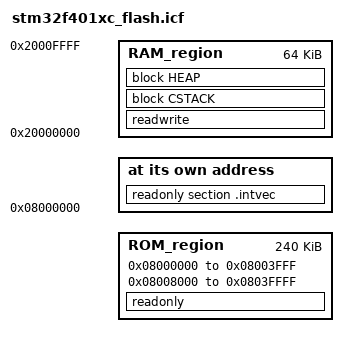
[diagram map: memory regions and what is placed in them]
/*###ICF### Section handled by ICF editor, don't touch! ****/
/*-Editor annotation file-*/
/* IcfEditorFile="$TOOLKIT_DIR$\config\ide\IcfEditor\cortex_v1_0.xml" */
/*-Specials-*/
define symbol __ICFEDIT_intvec_start__ = 0x08000000;
/*-Memory Regions-*/
define symbol __ICFEDIT_region_ROM_start__    = 0x08000000;
define symbol __ICFEDIT_region_ROM_end__      = 0x0803FFFF;
define symbol __ICFEDIT_region_RAM_start__    = 0x20000000;
define symbol __ICFEDIT_region_RAM_end__      = 0x2000FFFF;
/*-Sizes-*/
define symbol __ICFEDIT_size_cstack__ = 0x1000;
define symbol __ICFEDIT_size_heap__   = 0x3000;
/**** End of ICF editor section. ###ICF###*/

/*
  grbl_BlackPill, STM32F401CC (256 KB flash, 64 KB RAM).

  Flash layout:
    0x08000000  sector 0, 16 KB   vector table, then code
    0x08004000  sector 1, 16 KB   grblHAL settings (NVS), driver/nvs_flash.c
    0x08008000  sectors 2..       code and constants

  Sector 1 is left out of the ROM region so the linker never puts code
  there. The grblHAL core allocates memory with malloc() at startup
  (settings buffer, pin descriptions, ...): the heap must be at least 8 KB.
*/

define symbol __region_NVS_start__ = 0x08004000;
define symbol __region_NVS_end__   = 0x08007FFF;

define memory mem with size = 4G;
define region ROM_region      = mem:[from __ICFEDIT_region_ROM_start__ to (__region_NVS_start__ - 1)]
                              | mem:[from (__region_NVS_end__ + 1)   to __ICFEDIT_region_ROM_end__];
define region RAM_region      = mem:[from __ICFEDIT_region_RAM_start__ to __ICFEDIT_region_RAM_end__];

define block CSTACK    with alignment = 8, size = __ICFEDIT_size_cstack__   { };
define block HEAP      with alignment = 8, size = __ICFEDIT_size_heap__     { };

initialize by copy { readwrite };
do not initialize  { section .noinit };

place at address mem:__ICFEDIT_intvec_start__ { readonly section .intvec };

place in ROM_region   { readonly };
place in RAM_region   { readwrite,
                        block CSTACK, block HEAP };
